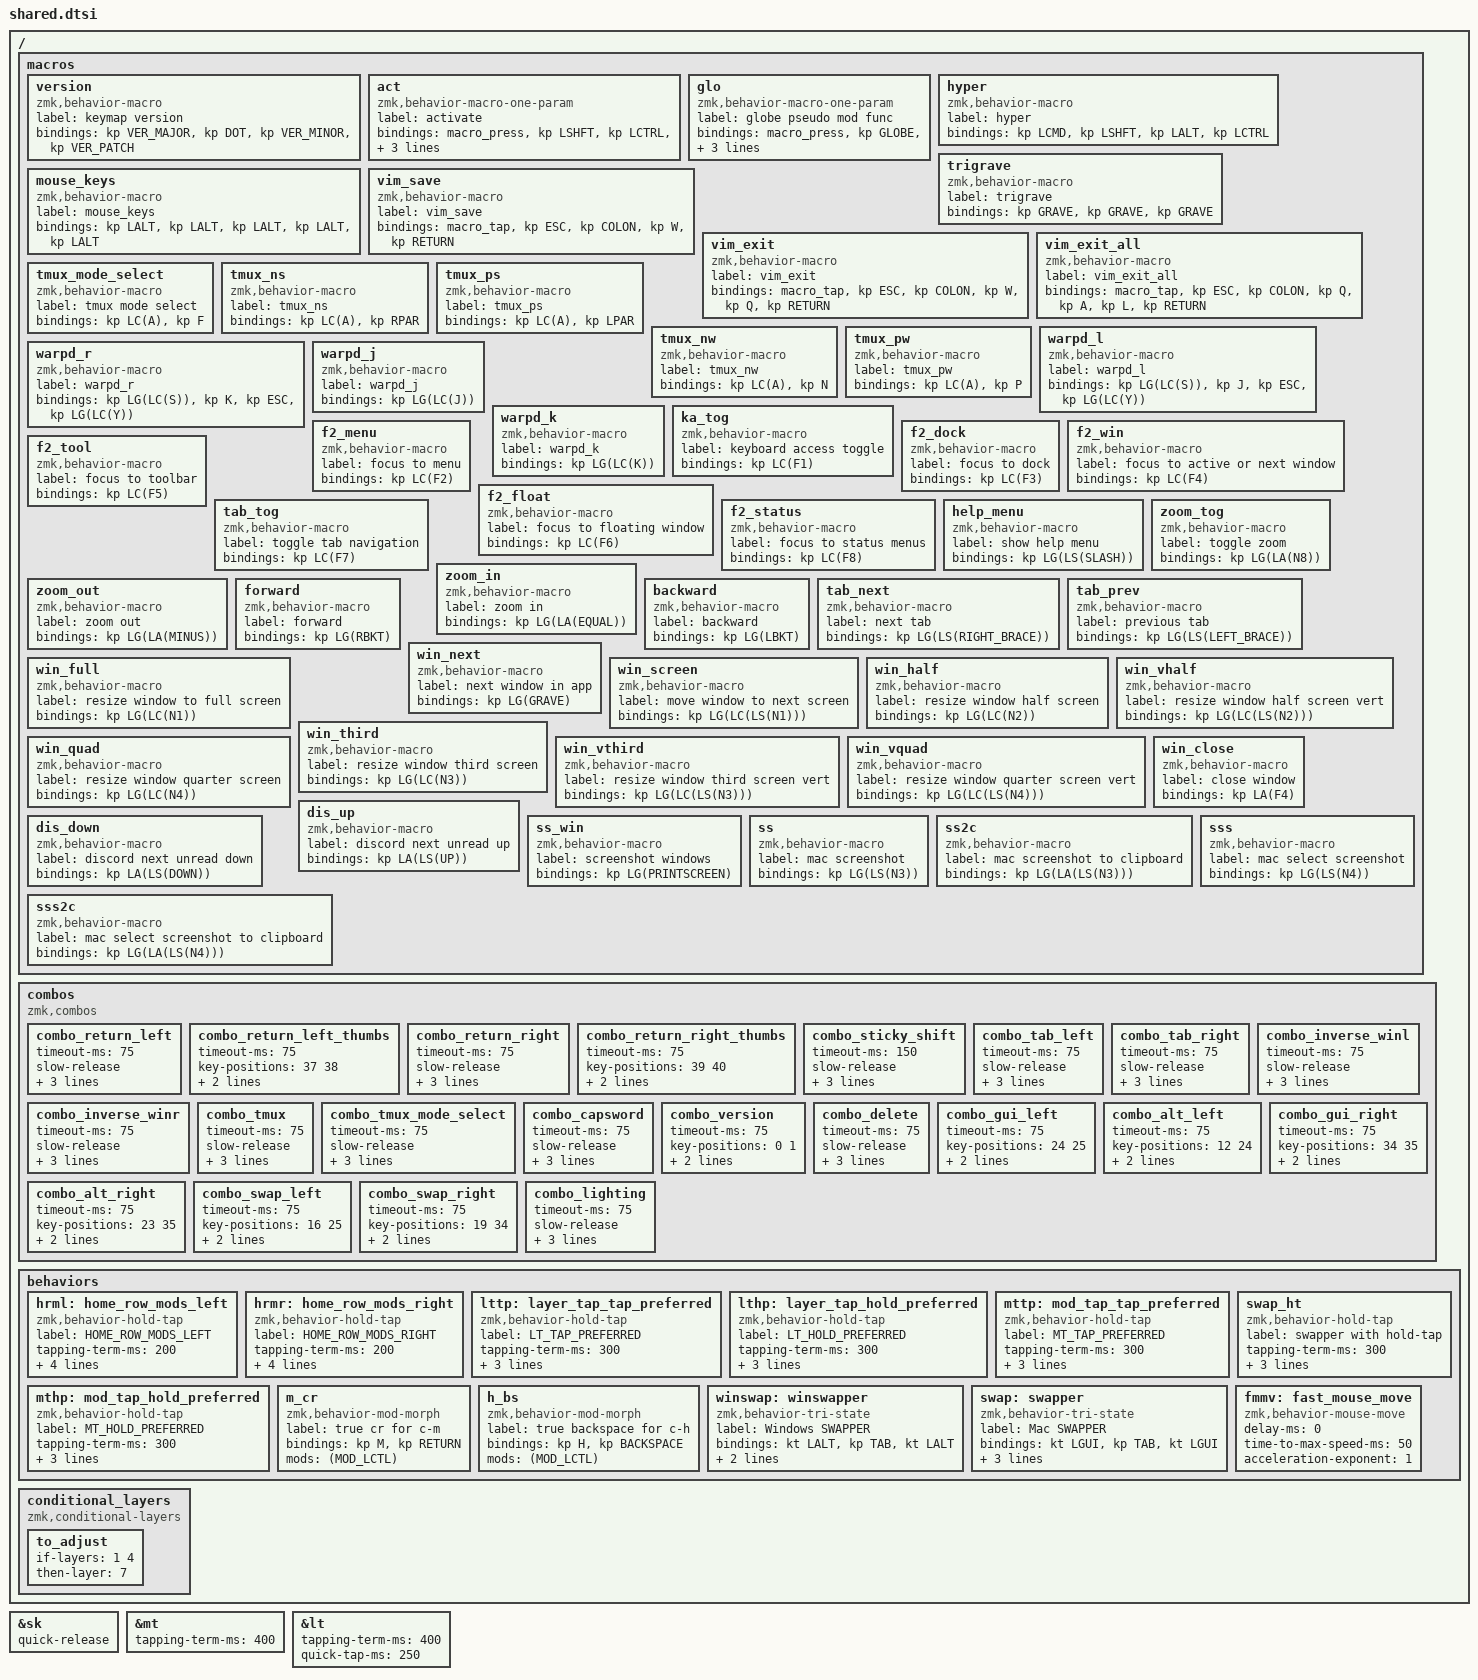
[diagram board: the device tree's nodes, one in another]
#define VER_PATCH N2
#define VER_MINOR N1
#define VER_MAJOR N2
/* Key Positions
╭────────────────────────╮ ╭────────────────────────╮
│  0   1   2   3   4   5 │ │  6   7   8   9  10  11 │
│ 12  13  14  15  16  17 │ │ 18  19  20  21  22  23 │
│ 24  25  26  27  28  29 │ │ 30  31  32  33  34  35 │
╰───────────╮ 36  37  38 │ │ 39  40  41 ╭───────────╯
            ╰────────────╯ ╰────────────╯
*/
// CONFIG {{{
&sk {
    quick-release;
};

&mt {
    tapping-term-ms = <400>;
};

&lt {
    tapping-term-ms = <400>;
    quick-tap-ms = <250>;
};
// }}}
/ {
// MACROS LAYERS {{{
    macros {
        version: version {
            compatible = "zmk,behavior-macro";
            label = "keymap version";
            #binding-cells = <0>;
            bindings = <&kp VER_MAJOR &kp DOT &kp VER_MINOR &kp VER_PATCH>;
        };
        act: act {
            compatible = "zmk,behavior-macro-one-param";
            label = "activate";
            #binding-cells = <1>;
            bindings
                = <&macro_press &kp LSHFT &kp LCTRL>
                , <&macro_param_1to1>
                , <&macro_tap &kp MACRO_PLACEHOLDER>
                , <&macro_release &kp LSHFT &kp LCTRL>
                ;
        };
        glo: glo {
            compatible = "zmk,behavior-macro-one-param";
            label = "globe pseudo mod func";
            #binding-cells = <1>;
            bindings
                = <&macro_press &kp GLOBE>
                , <&macro_param_1to1>
                , <&macro_tap &kp MACRO_PLACEHOLDER>
                , <&macro_release &kp GLOBE>
                ;
        };
        hyper: hyper {
            compatible = "zmk,behavior-macro";
            label = "hyper";
            #binding-cells = <0>;
            bindings = <&kp LCMD &kp LSHFT &kp LALT &kp LCTRL>;
        };
        trigrave: trigrave {
            compatible = "zmk,behavior-macro";
            label = "trigrave";
            #binding-cells = <0>;
            bindings = <&kp GRAVE &kp GRAVE &kp GRAVE>;
        };
        mouse_keys: mouse_keys {
            compatible = "zmk,behavior-macro";
            label = "mouse_keys";
            #binding-cells = <0>;
            bindings = <&kp LALT &kp LALT &kp LALT &kp LALT &kp LALT>;
        };
        vim_save: vim_save {
            compatible = "zmk,behavior-macro";
            label = "vim_save";
            #binding-cells = <0>;
            bindings =
                <&macro_tap>,
                <&kp ESC &kp COLON &kp W &kp RETURN>;
        };
        vim_exit: vim_exit {
            compatible = "zmk,behavior-macro";
            label = "vim_exit";
            #binding-cells = <0>;
            bindings =
                <&macro_tap>,
                <&kp ESC &kp COLON &kp W &kp Q &kp RETURN>;
        };
        vim_exit_all: vim_exit_all {
            compatible = "zmk,behavior-macro";
            label = "vim_exit_all";
            #binding-cells = <0>;
            bindings =
                <&macro_tap>,
                <&kp ESC &kp COLON &kp Q &kp A &kp L &kp RETURN>;
        };
        tmux_mode_select: tmux_mode_select {
            compatible = "zmk,behavior-macro";
            label = "tmux mode select";
            #binding-cells = <0>;
            bindings = <&kp LC(A) &kp F>;
        };
        tmux_ns: tmux_ns {
            compatible = "zmk,behavior-macro";
            label = "tmux_ns";
            #binding-cells = <0>;
            bindings = <&kp LC(A) &kp RPAR>;
        };
        tmux_ps: tmux_ps {
            compatible = "zmk,behavior-macro";
            label = "tmux_ps";
            #binding-cells = <0>;
            bindings = <&kp LC(A) &kp LPAR>;
        };
        tmux_nw: tmux_nw {
            compatible = "zmk,behavior-macro";
            label = "tmux_nw";
            #binding-cells = <0>;
            bindings = <&kp LC(A) &kp N>;
        };
        tmux_pw: tmux_pw {
            compatible = "zmk,behavior-macro";
            label = "tmux_pw";
            #binding-cells = <0>;
            bindings = <&kp LC(A) &kp P>;
        };
        warpd_l: warpd_l {
            compatible = "zmk,behavior-macro";
            label = "warpd_l";
            #binding-cells = <0>;
            bindings = <&kp LG(LC(S)) &kp J &kp ESC &kp LG(LC(Y))>;
        };
        warpd_r: warpd_r {
            compatible = "zmk,behavior-macro";
            label = "warpd_r";
            #binding-cells = <0>;
            bindings = <&kp LG(LC(S)) &kp K &kp ESC &kp LG(LC(Y))>;
        };
        warpd_j: warpd_j {
            compatible = "zmk,behavior-macro";
            label = "warpd_j";
            #binding-cells = <0>;
            bindings = <&kp LG(LC(J))>;
        };
        warpd_k: warpd_k {
            compatible = "zmk,behavior-macro";
            label = "warpd_k";
            #binding-cells = <0>;
            bindings = <&kp LG(LC(K))>;
        };
        ka_tog: ka_tog {
            compatible = "zmk,behavior-macro";
            label = "keyboard access toggle";
            #binding-cells = <0>;
            bindings = <&kp LC(F1)>;
        };
        f2_menu: f2_menu {
            compatible = "zmk,behavior-macro";
            label = "focus to menu";
            #binding-cells = <0>;
            bindings = <&kp LC(F2)>;
        };
        f2_dock: f2_dock {
            compatible = "zmk,behavior-macro";
            label = "focus to dock";
            #binding-cells = <0>;
            bindings = <&kp LC(F3)>;
        };
        f2_win: f2_win {
            compatible = "zmk,behavior-macro";
            label = "focus to active or next window";
            #binding-cells = <0>;
            bindings = <&kp LC(F4)>;
        };
        f2_tool: f2_tool {
            compatible = "zmk,behavior-macro";
            label = "focus to toolbar";
            #binding-cells = <0>;
            bindings = <&kp LC(F5)>;
        };
        f2_float: f2_float {
            compatible = "zmk,behavior-macro";
            label = "focus to floating window";
            #binding-cells = <0>;
            bindings = <&kp LC(F6)>;
        };
        tab_tog: tab_tog {
            compatible = "zmk,behavior-macro";
            label = "toggle tab navigation";
            #binding-cells = <0>;
            bindings = <&kp LC(F7)>;
        };
        f2_status: f2_status {
            compatible = "zmk,behavior-macro";
            label = "focus to status menus";
            #binding-cells = <0>;
            bindings = <&kp LC(F8)>;
        };
        help_menu: help_menu {
            compatible = "zmk,behavior-macro";
            label = "show help menu";
            #binding-cells = <0>;
            bindings = <&kp LG(LS(SLASH))>;
        };
        zoom_tog: zoom_tog {
            compatible = "zmk,behavior-macro";
            label = "toggle zoom";
            #binding-cells = <0>;
            bindings = <&kp LG(LA(N8))>;
        };
        zoom_in: zoom_in {
            compatible = "zmk,behavior-macro";
            label = "zoom in";
            #binding-cells = <0>;
            bindings = <&kp LG(LA(EQUAL))>;
        };
        zoom_out: zoom_out {
            compatible = "zmk,behavior-macro";
            label = "zoom out";
            #binding-cells = <0>;
            bindings = <&kp LG(LA(MINUS))>;
        };
        forward: forward {
            compatible = "zmk,behavior-macro";
            label = "forward";
            #binding-cells = <0>;
            bindings = <&kp LG(RBKT)>;
        };
        backward: backward {
            compatible = "zmk,behavior-macro";
            label = "backward";
            #binding-cells = <0>;
            bindings = <&kp LG(LBKT)>;
        };
        tab_next: tab_next {
            compatible = "zmk,behavior-macro";
            label = "next tab";
            #binding-cells = <0>;
            bindings = <&kp LG(LS(RIGHT_BRACE))>;
        };
        tab_prev: tab_prev {
            compatible = "zmk,behavior-macro";
            label = "previous tab";
            #binding-cells = <0>;
            bindings = <&kp LG(LS(LEFT_BRACE))>;
        };
        win_next: win_next {
            compatible = "zmk,behavior-macro";
            label = "next window in app";
            #binding-cells = <0>;
            bindings = <&kp LG(GRAVE)>;
        };
        win_full: win_full {
            compatible = "zmk,behavior-macro";
            label = "resize window to full screen";
            #binding-cells = <0>;
            bindings = <&kp LG(LC(N1))>;
        };
        win_screen: win_screen {
            compatible = "zmk,behavior-macro";
            label = "move window to next screen";
            #binding-cells = <0>;
            bindings = <&kp LG(LC(LS(N1)))>;
        };
        win_half: win_half {
            compatible = "zmk,behavior-macro";
            label = "resize window half screen";
            #binding-cells = <0>;
            bindings = <&kp LG(LC(N2))>;
        };
        win_vhalf: win_vhalf {
            compatible = "zmk,behavior-macro";
            label = "resize window half screen vert";
            #binding-cells = <0>;
            bindings = <&kp LG(LC(LS(N2)))>;
        };
        win_third: win_third {
            compatible = "zmk,behavior-macro";
            label = "resize window third screen";
            #binding-cells = <0>;
            bindings = <&kp LG(LC(N3))>;
        };
        win_vthird: win_vthird {
            compatible = "zmk,behavior-macro";
            label = "resize window third screen vert";
            #binding-cells = <0>;
            bindings = <&kp LG(LC(LS(N3)))>;
        };
        win_quad: win_quad {
            compatible = "zmk,behavior-macro";
            label = "resize window quarter screen";
            #binding-cells = <0>;
            bindings = <&kp LG(LC(N4))>;
        };
        win_vquad: win_vquad {
            compatible = "zmk,behavior-macro";
            label = "resize window quarter screen vert";
            #binding-cells = <0>;
            bindings = <&kp LG(LC(LS(N4)))>;
        };
        win_close: win_close {
            compatible = "zmk,behavior-macro";
            label = "close window";
            #binding-cells = <0>;
            bindings = <&kp LA(F4)>;
        };
        dis_up: dis_up {
            compatible = "zmk,behavior-macro";
            label = "discord next unread up";
            #binding-cells = <0>;
            bindings = <&kp LA(LS(UP))>;
        };
        dis_down: dis_down {
            compatible = "zmk,behavior-macro";
            label = "discord next unread down";
            #binding-cells = <0>;
            bindings = <&kp LA(LS(DOWN))>;
        };
        ss_win: ss_win {
            compatible = "zmk,behavior-macro";
            label = "screenshot windows";
            #binding-cells = <0>;
            bindings = <&kp LG(PRINTSCREEN)>;
        };
        ss: ss {
            compatible = "zmk,behavior-macro";
            label = "mac screenshot";
            #binding-cells = <0>;
            bindings = <&kp LG(LS(N3))>;
        };
        ss2c: ss2c {
            compatible = "zmk,behavior-macro";
            label = "mac screenshot to clipboard";
            #binding-cells = <0>;
            bindings = <&kp LG(LA(LS(N3)))>;
        };
        sss: sss {
            compatible = "zmk,behavior-macro";
            label = "mac select screenshot";
            #binding-cells = <0>;
            bindings = <&kp LG(LS(N4))>;
        };
        sss2c: sss2c {
            compatible = "zmk,behavior-macro";
            label = "mac select screenshot to clipboard";
            #binding-cells = <0>;
            bindings = <&kp LG(LA(LS(N4)))>;
        };

    };
// }}}
// COMBOS {{{
//   ╭────────────────────────╮ ╭────────────────────────╮
//   │  0   1   2   3   4   5 │ │  6   7   8   9  10  11 │
//   │ 12  13  14  15  16  17 │ │ 18  19  20  21  22  23 │
//   │ 24  25  26  27  28  29 │ │ 30  31  32  33  34  35 │
//   ╰───────────╮ 36  37  38 │ │ 39  40  41 ╭───────────╯
//               ╰────────────╯ ╰────────────╯
    combos {
        compatible = "zmk,combos";
        combo_return_left {
            timeout-ms = <75>;
            slow-release;
            key-positions = <5 17>;
            bindings = <&kp RETURN>;
            layers = <0>;
        };
        combo_return_left_thumbs {
            timeout-ms = <75>;
            key-positions = <37 38>;
            bindings = <&lthp 10 RETURN>;
            layers = <0>;
        };
        combo_return_right {
            timeout-ms = <75>;
            slow-release;
            key-positions = <6 18>;
            bindings = <&kp RETURN>;
            layers = <0>;
        };
        combo_return_right_thumbs {
            timeout-ms = <75>;
            key-positions = <39 40>;
            bindings = <&lthp 9 RETURN>;
            layers = <0>;
        };
        combo_sticky_shift {
            timeout-ms = <150>;
            slow-release;
            key-positions = <16 19>;
            bindings = <&sk LEFT_SHIFT>;
            layers = <0>;
        };
        combo_tab_left {
            timeout-ms = <75>;
            slow-release;
            key-positions = <17 29>;
            bindings = <&kp TAB>;
            layers = <0>;
        };
        combo_tab_right {
            timeout-ms = <75>;
            slow-release;
            key-positions = <18 30>;
            bindings = <&kp TAB>;
            layers = <0>;
        };
        combo_inverse_winl {
            timeout-ms = <75>;
            slow-release;
            key-positions = <0 38>;
            bindings = <&mo 6>;
            layers = <0>;
        };
        combo_inverse_winr {
            timeout-ms = <75>;
            slow-release;
            key-positions = <11 39>;
            bindings = <&mo 5>;
            layers = <0>;
        };
        combo_tmux {
            timeout-ms = <75>;
            slow-release;
            key-positions = <7 8 9>;
            bindings = <&kp LC(A)>;
            layers = <0>;
        };
        combo_tmux_mode_select {
            timeout-ms = <75>;
            slow-release;
            key-positions = <2 3 4>;
            bindings = <&tmux_mode_select>;
            layers = <0>;
        };
        combo_capsword {
            timeout-ms = <75>;
            slow-release;
            key-positions = <13 22>;
            bindings = <&caps_word>;
            layers = <0>;
        };
        combo_version {
            timeout-ms = <75>;
            key-positions = <0 1>;
            bindings = <&version>;
            layers = <0>;
        };
        combo_delete {
            timeout-ms = <75>;
            slow-release;
            key-positions = <10 11>;
            bindings = <&kp DELETE>;
            layers = <0>;
        };
        combo_gui_left {
            timeout-ms = <75>;
            key-positions = <24 25>;
            bindings = <&kp LGUI>;
            layers = <0>;
        };
        combo_alt_left {
            timeout-ms = <75>;
            key-positions = <12 24>;
            bindings = <&kp LALT>;
            layers = <0>;
        };
        combo_gui_right {
            timeout-ms = <75>;
            key-positions = <34 35>;
            bindings = <&kp LGUI>;
            layers = <0>;
        };
        combo_alt_right {
            timeout-ms = <75>;
            key-positions = <23 35>;
            bindings = <&kp LALT>;
            layers = <0>;
        };
        combo_swap_left {
            timeout-ms = <75>;
            key-positions = <16 25>;
            bindings = <&swap_ht 0 LG(TAB)>;
            layers = <0>;
        };
        combo_swap_right {
            timeout-ms = <75>;
            key-positions = <19 34>;
            bindings = <&swap_ht 0 LG(TAB)>;
            layers = <0>;
        };
       combo_lighting {
           timeout-ms = <75>;
           slow-release;
           key-positions = <0 11>;
           bindings = <&mo 8>;
           layers = <0>;
       };

    };

// }}}
// BEHAVIORS {{{
    behaviors {
        hrml: home_row_mods_left {
            compatible = "zmk,behavior-hold-tap";
            label = "HOME_ROW_MODS_LEFT";
            #binding-cells = <2>;
            tapping-term-ms = <200>;
            quick-tap-ms = <150>;
            flavor = "balanced";
            require-prior-idle-ms = <125>;
            //hold-trigger-key-positions = <list of all rhs keys>;
            //hold-trigger-on-release; // delay positional check until key release
            bindings =
                <&kp>,
                <&kp>;
        };
        hrmr: home_row_mods_right {
            compatible = "zmk,behavior-hold-tap";
            label = "HOME_ROW_MODS_RIGHT";
            #binding-cells = <2>;
            tapping-term-ms = <200>;
            quick-tap-ms = <150>;
            flavor = "balanced";
            require-prior-idle-ms = <125>;
            //hold-trigger-key-positions = <list of all lhs keys>;
            //hold-trigger-on-release; // delay positional check until key release
            bindings =
                <&kp>,
                <&kp>;
        };
        lttp: layer_tap_tap_preferred {
            compatible = "zmk,behavior-hold-tap";
            label = "LT_TAP_PREFERRED";
            #binding-cells = <2>;
            tapping-term-ms = <300>;
            quick-tap-ms = <150>;
            //require-prior-idle-ms = <125>;
            flavor = "tap-preferred";
            bindings =
                <&mo>,
                <&kp>;
        };
        lthp: layer_tap_hold_preferred {
            compatible = "zmk,behavior-hold-tap";
            label = "LT_HOLD_PREFERRED";
            #binding-cells = <2>;
            tapping-term-ms = <300>;
            quick-tap-ms = <150>;
            //require-prior-idle-ms = <125>;
            flavor = "hold-preferred";
            bindings =
                <&mo>,
                <&kp>;
        };
        mttp: mod_tap_tap_preferred {
            compatible = "zmk,behavior-hold-tap";
            label = "MT_TAP_PREFERRED";
            #binding-cells = <2>;
            tapping-term-ms = <300>;
            quick-tap-ms = <150>;
            //require-prior-idle-ms = <125>;
            flavor = "tap-preferred";
            bindings =
                <&kp>,
                <&kp>;
        };
        mthp: mod_tap_hold_preferred {
            compatible = "zmk,behavior-hold-tap";
            label = "MT_HOLD_PREFERRED";
            #binding-cells = <2>;
            tapping-term-ms = <300>;
            quick-tap-ms = <150>;
            //require-prior-idle-ms = <125>;
            flavor = "hold-preferred";
            bindings =
                <&kp>,
                <&kp>;
        };
        swap_ht: swap_ht {
            compatible = "zmk,behavior-hold-tap";
            label = "swapper with hold-tap";
            #binding-cells = <2>;
            tapping-term-ms = <300>;
            quick-tap-ms = <150>;
            flavor = "tap-preferred";
            bindings =
                <&swap>,
                <&kp>;
        };
        m_cr: m_cr {
            compatible = "zmk,behavior-mod-morph";
            label = "true cr for c-m";
            #binding-cells = <0>;
            bindings =
                <&kp M>,
                <&kp RETURN>;
            mods = <(MOD_LCTL)>;
        };
        h_bs: h_bs {
            compatible = "zmk,behavior-mod-morph";
            label = "true backspace for c-h";
            #binding-cells = <0>;
            bindings =
                <&kp H>,
                <&kp BACKSPACE>;
            mods = <(MOD_LCTL)>;
        };
        winswap: winswapper {
            compatible = "zmk,behavior-tri-state";
            label = "Windows SWAPPER";
            #binding-cells = <0>;
            bindings =
                <&kt LALT>,
                <&kp TAB>,
                <&kt LALT>;
            ignored-key-positions = <0 16 18 19 20 21 40>;
            ignored-layers = <0 3>;
        };
        swap: swapper {
            compatible = "zmk,behavior-tri-state";
            label = "Mac SWAPPER";
            #binding-cells = <0>;
            bindings =
                <&kt LGUI>,
                <&kp TAB>,
                <&kt LGUI>;
            // must include activating combo keys too (16 25, 19 34) or else tri-state will complete immediately for Mac
            // include hjkl (18 19 20 21) and nav layer activation (40) for navigation
            // include mode keys: h to hide (18), q to quit (1)
            ignored-key-positions = <1 16 18 19 20 21 25 34 40>;
            ignored-layers = <0 3>;
        };
        fmmv: fast_mouse_move {
            compatible = "zmk,behavior-mouse-move";
            #binding-cells = <1>;
            delay-ms = <0>;
            time-to-max-speed-ms = <50>;
            acceleration-exponent = <1>;
        };

    };
// }}}
// CONDITIONAL LAYERS {{{
    conditional_layers {
        compatible = "zmk,conditional-layers";

        to_adjust {
            if-layers = <1 4>;
            then-layer = <7>;
        };

        // provided by combo_lighting due to transparent layer issues
        //to_lighting {
        //    if-layers = <5 6>;
        //    then-layer = <8>;
        //};

        // replaced with combo layer-tap
        //to_discord {
        //    if-layers = <3 4>;
        //    then-layer = <9>;
        //};

    };
// }}}
};
/* vim: set ft=dts: */
